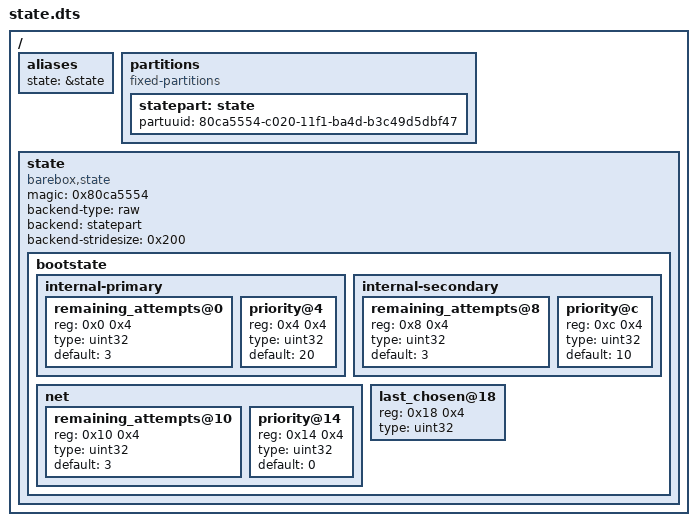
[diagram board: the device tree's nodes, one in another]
/dts-v1/;

/ {
	aliases {
		state = &state;
	};

	partitions {
		compatible = "fixed-partitions";

		statepart: state {
			partuuid = "80ca5554-c020-11f1-ba4d-b3c49d5dbf47";
		};
	};

	state: state {
		compatible = "barebox,state";
		magic = <0x80ca5554>;
		backend-type = "raw";
		backend = <&statepart>;
		backend-stridesize = <0x200>;
		#address-cells = <1>;
		#size-cells = <1>;

		bootstate {
			internal-primary {
				#address-cells = <1>;
				#size-cells = <1>;
				remaining_attempts@0 {
					reg = <0x0 0x4>;
					type = "uint32";
					default = <3>;
				};
				priority@4 {
					reg = <0x4 0x4>;
					type = "uint32";
					default = <20>;
				};
			};

			internal-secondary {
				#address-cells = <1>;
				#size-cells = <1>;
				remaining_attempts@8 {
					reg = <0x8 0x4>;
					type = "uint32";
					default = <3>;
				};
				priority@c {
					reg = <0xc 0x4>;
					type = "uint32";
					default = <10>;
				};
			};

			net {
				#address-cells = <1>;
				#size-cells = <1>;
				remaining_attempts@10 {
					reg = <0x10 0x4>;
					type = "uint32";
					default = <3>;
				};
				priority@14 {
					reg = <0x14 0x4>;
					type = "uint32";
					default = <0>;
				};
			};

			last_chosen@18 {
				#address-cells = <1>;
				#size-cells = <1>;
				reg = <0x18 0x4>;
				type = "uint32";
			};
		};
	};
};
